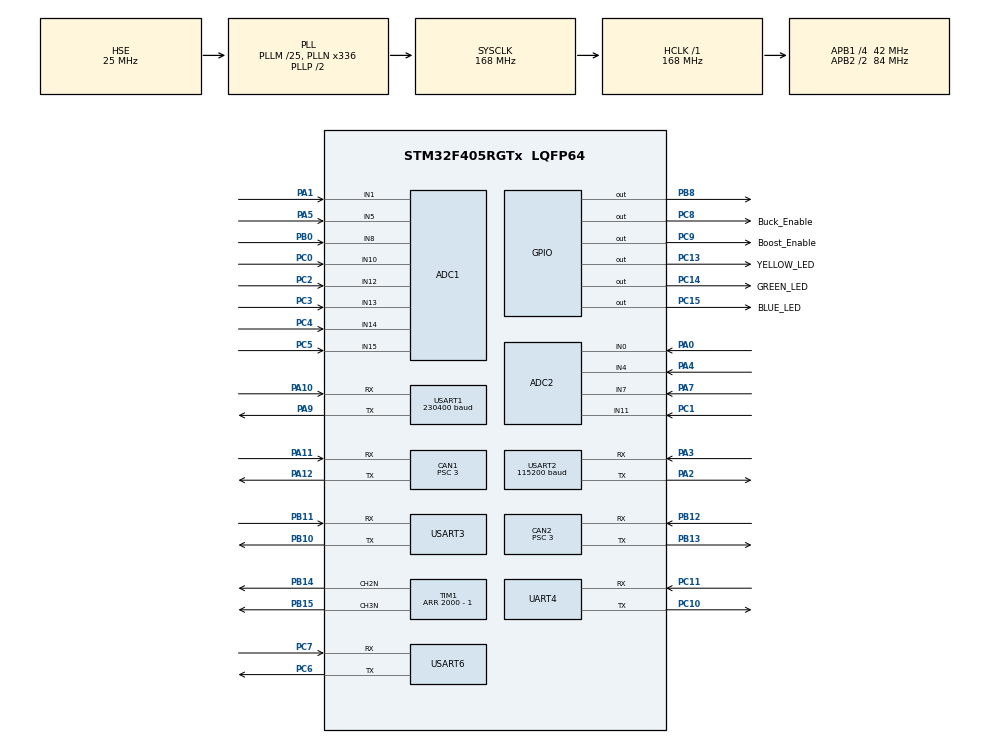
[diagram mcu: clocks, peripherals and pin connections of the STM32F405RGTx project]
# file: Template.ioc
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ADC1.Channel-0\#ChannelRegularConversion=ADC_CHANNEL_1
ADC1.Channel-1\#ChannelRegularConversion=ADC_CHANNEL_5
ADC1.Channel-2\#ChannelRegularConversion=ADC_CHANNEL_14
ADC1.Channel-3\#ChannelRegularConversion=ADC_CHANNEL_15
ADC1.Channel-4\#ChannelRegularConversion=ADC_CHANNEL_12
ADC1.Channel-5\#ChannelRegularConversion=ADC_CHANNEL_8
ADC1.Channel-6\#ChannelRegularConversion=ADC_CHANNEL_10
ADC1.Channel-7\#ChannelRegularConversion=ADC_CHANNEL_13
ADC1.ContinuousConvMode=ENABLE
ADC1.DMAContinuousRequests=ENABLE
ADC1.InjNumberOfConversion=0
ADC1.NbrOfConversion=8
ADC1.NbrOfConversionFlag=1
ADC1.Rank-0\#ChannelRegularConversion=1
ADC1.Rank-1\#ChannelRegularConversion=2
ADC1.Rank-2\#ChannelRegularConversion=3
ADC1.Rank-3\#ChannelRegularConversion=4
ADC1.Rank-4\#ChannelRegularConversion=5
ADC1.Rank-5\#ChannelRegularConversion=6
ADC1.Rank-6\#ChannelRegularConversion=7
ADC1.Rank-7\#ChannelRegularConversion=8
ADC1.SamplingTime-0\#ChannelRegularConversion=ADC_SAMPLETIME_56CYCLES
ADC1.SamplingTime-1\#ChannelRegularConversion=ADC_SAMPLETIME_56CYCLES
ADC1.SamplingTime-2\#ChannelRegularConversion=ADC_SAMPLETIME_56CYCLES
ADC1.SamplingTime-3\#ChannelRegularConversion=ADC_SAMPLETIME_56CYCLES
ADC1.SamplingTime-4\#ChannelRegularConversion=ADC_SAMPLETIME_56CYCLES
ADC1.SamplingTime-5\#ChannelRegularConversion=ADC_SAMPLETIME_56CYCLES
ADC1.SamplingTime-6\#ChannelRegularConversion=ADC_SAMPLETIME_56CYCLES
ADC1.SamplingTime-7\#ChannelRegularConversion=ADC_SAMPLETIME_56CYCLES
ADC1.ScanConvMode=ENABLE
ADC1.master=1
ADC2.Channel-0\#ChannelRegularConversion=ADC_CHANNEL_0
ADC2.Channel-2\#ChannelInjectedConversion=ADC_CHANNEL_0
ADC2.Channel-3\#ChannelInjectedConversion=ADC_CHANNEL_4
ADC2.Channel-4\#ChannelInjectedConversion=ADC_CHANNEL_11
ADC2.Channel-5\#ChannelInjectedConversion=ADC_CHANNEL_7
ADC2.ExternalTrigInjecConv=ADC_EXTERNALTRIGINJECCONV_T1_TRGO
ADC2.InjNumberOfConversion=4
ADC2.InjectedOffset-2\#ChannelInjectedConversion=0
ADC2.InjectedOffset-3\#ChannelInjectedConversion=0
ADC2.InjectedOffset-4\#ChannelInjectedConversion=0
ADC2.InjectedOffset-5\#ChannelInjectedConversion=0
ADC2.InjectedRank-2\#ChannelInjectedConversion=1
ADC2.InjectedRank-3\#ChannelInjectedConversion=2
ADC2.InjectedRank-4\#ChannelInjectedConversion=3
ADC2.InjectedRank-5\#ChannelInjectedConversion=4
ADC2.NbrOfConversion=1
ADC2.NbrOfConversionFlag=1
ADC2.Rank-0\#ChannelRegularConversion=1
ADC2.SamplingTime-0\#ChannelRegularConversion=ADC_SAMPLETIME_3CYCLES
ADC2.SamplingTime-2\#ChannelInjectedConversion=ADC_SAMPLETIME_56CYCLES
ADC2.SamplingTime-3\#ChannelInjectedConversion=ADC_SAMPLETIME_56CYCLES
ADC2.SamplingTime-4\#ChannelInjectedConversion=ADC_SAMPLETIME_56CYCLES
ADC2.SamplingTime-5\#ChannelInjectedConversion=ADC_SAMPLETIME_56CYCLES
CAN1.ABOM=ENABLE
CAN1.BS1=CAN_BS1_9TQ
CAN1.BS2=CAN_BS2_4TQ
CAN1.CalculateBaudRate=1000000
CAN1.CalculateTimeBit=1000
CAN1.CalculateTimeQuantum=71.42857142857143
CAN1.NART=ENABLE
CAN1.Prescaler=3
CAN2.ABOM=ENABLE
CAN2.BS1=CAN_BS1_9TQ
CAN2.BS2=CAN_BS2_4TQ
CAN2.CalculateBaudRate=1000000
CAN2.CalculateTimeBit=1000
CAN2.CalculateTimeQuantum=71.42857142857143
CAN2.NART=ENABLE
CAN2.Prescaler=3
Dma.ADC1.7.Direction=DMA_PERIPH_TO_MEMORY
Dma.ADC1.7.FIFOMode=DMA_FIFOMODE_DISABLE
Dma.ADC1.7.Instance=DMA2_Stream0
Dma.ADC1.7.MemDataAlignment=DMA_MDATAALIGN_WORD
Dma.ADC1.7.MemInc=DMA_MINC_ENABLE
Dma.ADC1.7.Mode=DMA_CIRCULAR
Dma.ADC1.7.PeriphDataAlignment=DMA_PDATAALIGN_WORD
Dma.ADC1.7.PeriphInc=DMA_PINC_DISABLE
Dma.ADC1.7.Priority=DMA_PRIORITY_LOW
Dma.Request0=USART1_RX
Dma.Request1=USART1_TX
Dma.Request10=UART4_TX
Dma.Request2=USART3_RX
Dma.Request3=USART3_TX
Dma.Request4=USART6_RX
Dma.Request5=USART6_TX
Dma.Request6=USART2_RX
Dma.Request7=ADC1
Dma.Request8=USART2_TX
Dma.Request9=UART4_RX
Dma.UART4_RX.9.Direction=DMA_PERIPH_TO_MEMORY
Dma.UART4_RX.9.FIFOMode=DMA_FIFOMODE_DISABLE
Dma.UART4_RX.9.Instance=DMA1_Stream2
Dma.UART4_RX.9.MemDataAlignment=DMA_MDATAALIGN_BYTE
Dma.UART4_RX.9.MemInc=DMA_MINC_ENABLE
Dma.UART4_RX.9.Mode=DMA_NORMAL
Dma.UART4_RX.9.PeriphDataAlignment=DMA_PDATAALIGN_BYTE
Dma.UART4_RX.9.PeriphInc=DMA_PINC_DISABLE
Dma.UART4_RX.9.Priority=DMA_PRIORITY_LOW
Dma.UART4_TX.10.Direction=DMA_MEMORY_TO_PERIPH
Dma.UART4_TX.10.FIFOMode=DMA_FIFOMODE_DISABLE
Dma.UART4_TX.10.Instance=DMA1_Stream4
Dma.UART4_TX.10.MemDataAlignment=DMA_MDATAALIGN_BYTE
Dma.UART4_TX.10.MemInc=DMA_MINC_ENABLE
Dma.UART4_TX.10.Mode=DMA_NORMAL
Dma.UART4_TX.10.PeriphDataAlignment=DMA_PDATAALIGN_BYTE
Dma.UART4_TX.10.PeriphInc=DMA_PINC_DISABLE
Dma.UART4_TX.10.Priority=DMA_PRIORITY_LOW
Dma.USART1_RX.0.Direction=DMA_PERIPH_TO_MEMORY
Dma.USART1_RX.0.FIFOMode=DMA_FIFOMODE_DISABLE
Dma.USART1_RX.0.Instance=DMA2_Stream2
Dma.USART1_RX.0.MemDataAlignment=DMA_MDATAALIGN_BYTE
Dma.USART1_RX.0.MemInc=DMA_MINC_ENABLE
Dma.USART1_RX.0.Mode=DMA_NORMAL
Dma.USART1_RX.0.PeriphDataAlignment=DMA_PDATAALIGN_BYTE
Dma.USART1_RX.0.PeriphInc=DMA_PINC_DISABLE
Dma.USART1_RX.0.Priority=DMA_PRIORITY_LOW
Dma.USART1_TX.1.Direction=DMA_MEMORY_TO_PERIPH
Dma.USART1_TX.1.FIFOMode=DMA_FIFOMODE_DISABLE
Dma.USART1_TX.1.Instance=DMA2_Stream7
Dma.USART1_TX.1.MemDataAlignment=DMA_MDATAALIGN_BYTE
Dma.USART1_TX.1.MemInc=DMA_MINC_ENABLE
Dma.USART1_TX.1.Mode=DMA_NORMAL
Dma.USART1_TX.1.PeriphDataAlignment=DMA_PDATAALIGN_BYTE
Dma.USART1_TX.1.PeriphInc=DMA_PINC_DISABLE
Dma.USART1_TX.1.Priority=DMA_PRIORITY_LOW
Dma.USART2_RX.6.Direction=DMA_PERIPH_TO_MEMORY
Dma.USART2_RX.6.FIFOMode=DMA_FIFOMODE_DISABLE
Dma.USART2_RX.6.Instance=DMA1_Stream5
Dma.USART2_RX.6.MemDataAlignment=DMA_MDATAALIGN_BYTE
Dma.USART2_RX.6.MemInc=DMA_MINC_ENABLE
Dma.USART2_RX.6.Mode=DMA_NORMAL
Dma.USART2_RX.6.PeriphDataAlignment=DMA_PDATAALIGN_BYTE
Dma.USART2_RX.6.PeriphInc=DMA_PINC_DISABLE
Dma.USART2_RX.6.Priority=DMA_PRIORITY_LOW
Dma.USART2_TX.8.Direction=DMA_MEMORY_TO_PERIPH
Dma.USART2_TX.8.FIFOMode=DMA_FIFOMODE_DISABLE
Dma.USART2_TX.8.Instance=DMA1_Stream6
Dma.USART2_TX.8.MemDataAlignment=DMA_MDATAALIGN_BYTE
Dma.USART2_TX.8.MemInc=DMA_MINC_ENABLE
Dma.USART2_TX.8.Mode=DMA_NORMAL
Dma.USART2_TX.8.PeriphDataAlignment=DMA_PDATAALIGN_BYTE
Dma.USART2_TX.8.PeriphInc=DMA_PINC_DISABLE
Dma.USART2_TX.8.Priority=DMA_PRIORITY_LOW
Dma.USART3_RX.2.Direction=DMA_PERIPH_TO_MEMORY
Dma.USART3_RX.2.FIFOMode=DMA_FIFOMODE_DISABLE
Dma.USART3_RX.2.Instance=DMA1_Stream1
Dma.USART3_RX.2.MemDataAlignment=DMA_MDATAALIGN_BYTE
Dma.USART3_RX.2.MemInc=DMA_MINC_ENABLE
Dma.USART3_RX.2.Mode=DMA_NORMAL
Dma.USART3_RX.2.PeriphDataAlignment=DMA_PDATAALIGN_BYTE
Dma.USART3_RX.2.PeriphInc=DMA_PINC_DISABLE
Dma.USART3_RX.2.Priority=DMA_PRIORITY_LOW
Dma.USART3_TX.3.Direction=DMA_MEMORY_TO_PERIPH
Dma.USART3_TX.3.FIFOMode=DMA_FIFOMODE_DISABLE
Dma.USART3_TX.3.Instance=DMA1_Stream3
Dma.USART3_TX.3.MemDataAlignment=DMA_MDATAALIGN_BYTE
Dma.USART3_TX.3.MemInc=DMA_MINC_ENABLE
Dma.USART3_TX.3.Mode=DMA_NORMAL
Dma.USART3_TX.3.PeriphDataAlignment=DMA_PDATAALIGN_BYTE
Dma.USART3_TX.3.PeriphInc=DMA_PINC_DISABLE
Dma.USART3_TX.3.Priority=DMA_PRIORITY_LOW
Dma.USART6_RX.4.Direction=DMA_PERIPH_TO_MEMORY
Dma.USART6_RX.4.FIFOMode=DMA_FIFOMODE_DISABLE
Dma.USART6_RX.4.Instance=DMA2_Stream1
Dma.USART6_RX.4.MemDataAlignment=DMA_MDATAALIGN_BYTE
Dma.USART6_RX.4.MemInc=DMA_MINC_ENABLE
Dma.USART6_RX.4.Mode=DMA_NORMAL
Dma.USART6_RX.4.PeriphDataAlignment=DMA_PDATAALIGN_BYTE
Dma.USART6_RX.4.PeriphInc=DMA_PINC_DISABLE
Dma.USART6_RX.4.Priority=DMA_PRIORITY_LOW
Dma.USART6_TX.5.Direction=DMA_MEMORY_TO_PERIPH
Dma.USART6_TX.5.FIFOMode=DMA_FIFOMODE_DISABLE
Dma.USART6_TX.5.Instance=DMA2_Stream6
Dma.USART6_TX.5.MemDataAlignment=DMA_MDATAALIGN_BYTE
Dma.USART6_TX.5.MemInc=DMA_MINC_ENABLE
Dma.USART6_TX.5.Mode=DMA_NORMAL
Dma.USART6_TX.5.PeriphDataAlignment=DMA_PDATAALIGN_BYTE
Dma.USART6_TX.5.PeriphInc=DMA_PINC_DISABLE
Dma.USART6_TX.5.Priority=DMA_PRIORITY_LOW
FREERTOS.INCLUDE_vTaskDelayUntil=1
FREERTOS.Tasks01=defaultTask,0,128,StartDefaultTask,Default,NULL
FREERTOS.configMAX_PRIORITIES=9
Mcu.Family=STM32F4
Mcu.Name=STM32F405RGTx
Mcu.Package=LQFP64
NVIC.ADC_IRQn=true\:0\:0\:true\:false\:true\:false\:true\:true\:true
NVIC.CAN1_RX0_IRQn=true\:5\:0\:false\:false\:true\:true\:true\:true\:true
NVIC.CAN1_RX1_IRQn=true\:5\:0\:false\:false\:true\:true\:true\:true\:true
NVIC.CAN2_RX0_IRQn=true\:5\:0\:false\:false\:true\:true\:true\:true\:true
NVIC.CAN2_RX1_IRQn=true\:5\:0\:false\:false\:true\:true\:true\:true\:true
NVIC.DMA1_Stream1_IRQn=true\:5\:0\:false\:false\:true\:true\:false\:true\:true
NVIC.DMA1_Stream2_IRQn=true\:5\:0\:false\:false\:true\:true\:true\:true\:true
NVIC.DMA1_Stream3_IRQn=true\:5\:0\:false\:false\:true\:true\:true\:true\:true
NVIC.DMA1_Stream4_IRQn=true\:5\:0\:false\:false\:true\:true\:true\:true\:true
NVIC.DMA1_Stream5_IRQn=true\:5\:0\:false\:false\:true\:true\:false\:true\:true
NVIC.DMA1_Stream6_IRQn=true\:5\:0\:false\:false\:true\:true\:true\:true\:true
NVIC.DMA2_Stream1_IRQn=true\:5\:0\:false\:false\:true\:true\:false\:true\:true
NVIC.DMA2_Stream2_IRQn=true\:5\:0\:false\:false\:true\:true\:false\:true\:true
NVIC.DMA2_Stream6_IRQn=true\:5\:0\:false\:false\:true\:true\:true\:true\:true
NVIC.DMA2_Stream7_IRQn=true\:5\:0\:false\:false\:true\:true\:true\:true\:true
NVIC.PriorityGroup=NVIC_PRIORITYGROUP_4
NVIC.TIM1_UP_TIM10_IRQn=true\:5\:0\:false\:false\:true\:true\:true\:true\:true
NVIC.TIM4_IRQn=true\:5\:0\:false\:false\:true\:true\:true\:true\:true
NVIC.TIM7_IRQn=true\:15\:0\:false\:false\:true\:false\:false\:true\:true
NVIC.TimeBase=TIM7_IRQn
NVIC.TimeBaseIP=TIM7
NVIC.UART4_IRQn=true\:5\:0\:false\:false\:true\:true\:true\:true\:true
NVIC.USART1_IRQn=true\:5\:0\:false\:false\:true\:true\:true\:true\:true
NVIC.USART2_IRQn=true\:5\:0\:false\:false\:true\:true\:true\:true\:true
NVIC.USART3_IRQn=true\:5\:0\:false\:false\:true\:true\:true\:true\:true
NVIC.USART6_IRQn=true\:5\:0\:false\:false\:true\:true\:true\:true\:true
PA0-WKUP.GPIO_Mode=GPIO_MODE_ANALOG
PA0-WKUP.GPIO_PuPd=GPIO_NOPULL
PA0-WKUP.Signal=ADCx_IN0
PA1.GPIO_Mode=GPIO_MODE_ANALOG
PA1.GPIO_PuPd=GPIO_NOPULL
PA1.Signal=ADCx_IN1
PA10.GPIO_PuPd=GPIO_PULLUP
PA10.Mode=Asynchronous
PA10.Signal=USART1_RX
PA11.GPIO_PuPd=GPIO_NOPULL
PA11.Mode=CAN_Activate
PA11.Signal=CAN1_RX
PA12.GPIO_PuPd=GPIO_NOPULL
PA12.Mode=CAN_Activate
PA12.Signal=CAN1_TX
PA13.Mode=Serial_Wire
PA13.Signal=SYS_JTMS-SWDIO
PA14.Mode=Serial_Wire
PA14.Signal=SYS_JTCK-SWCLK
PA2.GPIO_PuPd=GPIO_NOPULL
PA2.Mode=Asynchronous
PA2.Signal=USART2_TX
PA3.GPIO_PuPd=GPIO_PULLUP
PA3.Mode=Asynchronous
PA3.Signal=USART2_RX
PA4.GPIO_Mode=GPIO_MODE_ANALOG
PA4.GPIO_PuPd=GPIO_NOPULL
PA4.Signal=ADCx_IN4
PA5.GPIO_Mode=GPIO_MODE_ANALOG
PA5.GPIO_PuPd=GPIO_NOPULL
PA5.Signal=ADCx_IN5
PA7.Signal=ADCx_IN7
PA9.GPIO_PuPd=GPIO_NOPULL
PA9.Mode=Asynchronous
PA9.Signal=USART1_TX
PB0.GPIO_Mode=GPIO_MODE_ANALOG
PB0.GPIO_PuPd=GPIO_NOPULL
PB0.Signal=ADCx_IN8
PB10.GPIO_PuPd=GPIO_NOPULL
PB10.Mode=Asynchronous
PB10.Signal=USART3_TX
PB11.GPIO_PuPd=GPIO_PULLUP
PB11.Mode=Asynchronous
PB11.Signal=USART3_RX
PB12.GPIO_PuPd=GPIO_NOPULL
PB12.Mode=CAN_Activate
PB12.Signal=CAN2_RX
PB13.GPIO_PuPd=GPIO_NOPULL
PB13.Mode=CAN_Activate
PB13.Signal=CAN2_TX
PB14.GPIO_PuPd=GPIO_NOPULL
PB14.Mode=PWM Generation2 CH2N
PB14.Signal=TIM1_CH2N
PB15.GPIO_PuPd=GPIO_NOPULL
PB15.Mode=PWM Generation3 CH3N
PB15.Signal=TIM1_CH3N
PB8.Signal=GPIO_Output
PC0.GPIO_Mode=GPIO_MODE_ANALOG
PC0.GPIO_PuPd=GPIO_NOPULL
PC0.Signal=ADCx_IN10
PC1.GPIO_Mode=GPIO_MODE_ANALOG
PC1.GPIO_PuPd=GPIO_NOPULL
PC1.Signal=ADCx_IN11
PC10.GPIO_PuPd=GPIO_NOPULL
PC10.Mode=Asynchronous
PC10.Signal=UART4_TX
PC11.GPIO_PuPd=GPIO_PULLUP
PC11.Mode=Asynchronous
PC11.Signal=UART4_RX
PC13-ANTI_TAMP.GPIO_Label=YELLOW_LED
PC13-ANTI_TAMP.GPIO_PuPd=GPIO_NOPULL
PC13-ANTI_TAMP.PinState=GPIO_PIN_SET
PC13-ANTI_TAMP.Signal=GPIO_Output
PC14-OSC32_IN.GPIO_Label=GREEN_LED
PC14-OSC32_IN.GPIO_PuPd=GPIO_NOPULL
PC14-OSC32_IN.PinState=GPIO_PIN_SET
PC14-OSC32_IN.Signal=GPIO_Output
PC15-OSC32_OUT.GPIO_Label=BLUE_LED
PC15-OSC32_OUT.GPIO_PuPd=GPIO_NOPULL
PC15-OSC32_OUT.PinState=GPIO_PIN_SET
PC15-OSC32_OUT.Signal=GPIO_Output
PC2.GPIO_Mode=GPIO_MODE_ANALOG
PC2.GPIO_PuPd=GPIO_NOPULL
PC2.Signal=ADCx_IN12
PC3.GPIO_Mode=GPIO_MODE_ANALOG
PC3.GPIO_PuPd=GPIO_NOPULL
PC3.Signal=ADCx_IN13
PC4.GPIO_Mode=GPIO_MODE_ANALOG
PC4.GPIO_PuPd=GPIO_NOPULL
PC4.Signal=ADCx_IN14
PC5.GPIO_Mode=GPIO_MODE_ANALOG
PC5.GPIO_PuPd=GPIO_NOPULL
PC5.Signal=ADCx_IN15
PC6.GPIO_PuPd=GPIO_NOPULL
PC6.Mode=Asynchronous
PC6.Signal=USART6_TX
PC7.GPIO_PuPd=GPIO_PULLUP
PC7.Mode=Asynchronous
PC7.Signal=USART6_RX
PC8.GPIO_Label=Buck_Enable
PC8.GPIO_PuPd=GPIO_NOPULL
PC8.GPIO_Speed=GPIO_SPEED_FREQ_LOW
PC8.PinState=GPIO_PIN_RESET
PC8.Signal=GPIO_Output
PC9.GPIO_Label=Boost_Enable
PC9.GPIO_PuPd=GPIO_NOPULL
PC9.GPIO_Speed=GPIO_SPEED_FREQ_LOW
PC9.PinState=GPIO_PIN_RESET
PC9.Signal=GPIO_Output
PH0-OSC_IN.Mode=HSE-External-Oscillator
PH0-OSC_IN.Signal=RCC_OSC_IN
PH1-OSC_OUT.Mode=HSE-External-Oscillator
PH1-OSC_OUT.Signal=RCC_OSC_OUT
ProjectManager.HeapSize=0x200
ProjectManager.StackSize=0x400
ProjectManager.TargetToolchain=MDK-ARM V5.27
RCC.48MHZClocksFreq_Value=48000000
RCC.AHBFreq_Value=168000000
RCC.APB1CLKDivider=RCC_HCLK_DIV4
RCC.APB1Freq_Value=42000000
RCC.APB1TimFreq_Value=84000000
RCC.APB2CLKDivider=RCC_HCLK_DIV2
RCC.APB2Freq_Value=84000000
RCC.APB2TimFreq_Value=168000000
RCC.CortexFreq_Value=168000000
RCC.HCLKFreq_Value=168000000
RCC.HSE_VALUE=25000000
RCC.HSI_VALUE=16000000
RCC.LSE_VALUE=32768
RCC.PLLM=25
RCC.PLLN=336
RCC.PLLQ=7
RCC.PLLSourceVirtual=RCC_PLLSOURCE_HSE
RCC.SYSCLKFreq_VALUE=168000000
RCC.SYSCLKSource=RCC_SYSCLKSOURCE_PLLCLK
RCC.VCOOutputFreq_Value=336000000
SH.ADCx_IN0.0=ADC2_IN0,IN0
SH.ADCx_IN1.0=ADC1_IN1,IN1
SH.ADCx_IN10.0=ADC1_IN10,IN10
SH.ADCx_IN11.0=ADC2_IN11,IN11
SH.ADCx_IN12.0=ADC1_IN12,IN12
SH.ADCx_IN13.0=ADC1_IN13,IN13
SH.ADCx_IN14.0=ADC1_IN14,IN14
SH.ADCx_IN15.0=ADC1_IN15,IN15
SH.ADCx_IN4.0=ADC2_IN4,IN4
SH.ADCx_IN5.0=ADC1_IN5,IN5
SH.ADCx_IN7.0=ADC2_IN7,IN7
SH.ADCx_IN8.0=ADC1_IN8,IN8
TIM1.Channel-PWM\ Generation2\ CH2N=TIM_CHANNEL_2
TIM1.Channel-PWM\ Generation3\ CH3N=TIM_CHANNEL_3
TIM1.CounterMode=TIM_COUNTERMODE_CENTERALIGNED3
TIM1.OCFastMode_PWM-PWM\ Generation2\ CH2N=TIM_OCFAST_ENABLE
TIM1.OCFastMode_PWM-PWM\ Generation3\ CH3N=TIM_OCFAST_ENABLE
TIM1.Period=2000 - 1
TIM1.TIM_MasterOutputTrigger=TIM_TRGO_UPDATE
TIM4.Prescaler=83
UART4.VirtualMode=Asynchronous
USART1.BaudRate=230400
USART1.VirtualMode=VM_ASYNC
USART2.BaudRate=115200
USART2.Mode=MODE_TX_RX
USART2.Parity=PARITY_NONE
USART2.VirtualMode=VM_ASYNC
USART2.WordLength=WORDLENGTH_8B
USART3.VirtualMode=VM_ASYNC
USART6.VirtualMode=VM_ASYNC
VP_FREERTOS_VS_CMSIS_V1.Mode=CMSIS_V1
VP_SYS_VS_tim7.Mode=TIM7
VP_TIM4_VS_ClockSourceINT.Mode=Internal
board=custom

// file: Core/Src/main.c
/* USER CODE BEGIN Header */
/**
  ******************************************************************************
  * @file           : main.c
  * @brief          : Main program body
  ******************************************************************************
  * @attention
  *
  * <h2><center>&copy; Copyright (c) 2019 STMicroelectronics.
  * All rights reserved.</center></h2>
  *
  * This software component is licensed by ST under Ultimate Liberty license
  * SLA0044, the "License"; You may not use this file except in compliance with
  * the License. You may obtain a copy of the License at:
  *                             www.st.com/SLA0044
  *
  ******************************************************************************
  */
/* USER CODE END Header */
#include "main.h"
#include "cmsis_os.h"
#include "adc.h"
#include "can.h"
#include "dma.h"
#include "tim.h"
#include "usart.h"
#include "gpio.h"

/* USER CODE BEGIN Includes */
#include "SRML.h"
/* USER CODE END Includes */

void SystemClock_Config(void);
void MX_FREERTOS_Init(void);

int main(void)
{

  /* MCU Configuration--------------------------------------------------------*/

  /* Reset of all peripherals, Initializes the Flash interface and the Systick. */
  HAL_Init();

  /* Configure the system clock */
  SystemClock_Config();

  /* Initialize all configured peripherals */
  MX_GPIO_Init();
  MX_DMA_Init();
  MX_CAN1_Init();
  MX_CAN2_Init();
  MX_USART1_UART_Init();
  MX_USART2_UART_Init();
  MX_USART3_UART_Init();
  MX_USART6_UART_Init();
  MX_ADC1_Init();
  MX_TIM1_Init();
  MX_TIM4_Init();
  MX_UART4_Init();
  MX_ADC2_Init();
  /* USER CODE BEGIN 2 */
  System_Device_Init();
  /* USER CODE END 2 */

  /* Call init function for freertos objects (in freertos.c) */
  MX_FREERTOS_Init();

  /* Start scheduler */
  osKernelStart();

  /* We should never get here as control is now taken by the scheduler */
  /* Infinite loop */
  while (1)
  {

  }
}

void SystemClock_Config(void)
{
  RCC_OscInitTypeDef RCC_OscInitStruct = {0};
  RCC_ClkInitTypeDef RCC_ClkInitStruct = {0};

  /** Configure the main internal regulator output voltage
  */
  __HAL_RCC_PWR_CLK_ENABLE();
  __HAL_PWR_VOLTAGESCALING_CONFIG(PWR_REGULATOR_VOLTAGE_SCALE1);

  /** Initializes the RCC Oscillators according to the specified parameters
  * in the RCC_OscInitTypeDef structure.
  */
  RCC_OscInitStruct.OscillatorType = RCC_OSCILLATORTYPE_HSE;
  RCC_OscInitStruct.HSEState = RCC_HSE_ON;
  RCC_OscInitStruct.PLL.PLLState = RCC_PLL_ON;
  RCC_OscInitStruct.PLL.PLLSource = RCC_PLLSOURCE_HSE;
  RCC_OscInitStruct.PLL.PLLM = 25;
  RCC_OscInitStruct.PLL.PLLN = 336;
  RCC_OscInitStruct.PLL.PLLP = RCC_PLLP_DIV2;
  RCC_OscInitStruct.PLL.PLLQ = 7;
  if (HAL_RCC_OscConfig(&RCC_OscInitStruct) != HAL_OK)
  {
    Error_Handler();
  }

  /** Initializes the CPU, AHB and APB buses clocks
  */
  RCC_ClkInitStruct.ClockType = RCC_CLOCKTYPE_HCLK|RCC_CLOCKTYPE_SYSCLK
                              |RCC_CLOCKTYPE_PCLK1|RCC_CLOCKTYPE_PCLK2;
  RCC_ClkInitStruct.SYSCLKSource = RCC_SYSCLKSOURCE_PLLCLK;
  RCC_ClkInitStruct.AHBCLKDivider = RCC_SYSCLK_DIV1;
  RCC_ClkInitStruct.APB1CLKDivider = RCC_HCLK_DIV4;
  RCC_ClkInitStruct.APB2CLKDivider = RCC_HCLK_DIV2;

  if (HAL_RCC_ClockConfig(&RCC_ClkInitStruct, FLASH_LATENCY_5) != HAL_OK)
  {
    Error_Handler();
  }
}

void HAL_TIM_PeriodElapsedCallback(TIM_HandleTypeDef *htim)
{
  /* USER CODE BEGIN Callback 0 */
  if (htim->Instance == TIM4) {
    Update_SystemTick();
  }
  /* USER CODE END Callback 0 */
  if (htim->Instance == TIM7) {
    HAL_IncTick();
  }
}

void Error_Handler(void)
{
}

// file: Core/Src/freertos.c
/* USER CODE BEGIN Header */
/**
  ******************************************************************************
  * File Name          : freertos.c
  * Description        : Code for freertos applications
  ******************************************************************************
  * @attention
  *
  * <h2><center>&copy; Copyright (c) 2019 STMicroelectronics.
  * All rights reserved.</center></h2>
  *
  * This software component is licensed by ST under Ultimate Liberty license
  * SLA0044, the "License"; You may not use this file except in compliance with
  * the License. You may obtain a copy of the License at:
  *                             www.st.com/SLA0044
  *
  ******************************************************************************
  */
/* USER CODE END Header */

#include "FreeRTOS.h"
#include "task.h"
#include "main.h"
#include "cmsis_os.h"

osThreadId defaultTaskHandle;

void StartDefaultTask(void const * argument);

void MX_FREERTOS_Init(void); /* (MISRA C 2004 rule 8.1) */

/* GetIdleTaskMemory prototype (linked to static allocation support) */
void vApplicationGetIdleTaskMemory( StaticTask_t **ppxIdleTaskTCBBuffer, StackType_t **ppxIdleTaskStackBuffer, uint32_t *pulIdleTaskStackSize );

/* USER CODE BEGIN GET_IDLE_TASK_MEMORY */
static StaticTask_t xIdleTaskTCBBuffer;
static StackType_t xIdleStack[configMINIMAL_STACK_SIZE];

void vApplicationGetIdleTaskMemory( StaticTask_t **ppxIdleTaskTCBBuffer, StackType_t **ppxIdleTaskStackBuffer, uint32_t *pulIdleTaskStackSize )
{
  *ppxIdleTaskTCBBuffer = &xIdleTaskTCBBuffer;
  *ppxIdleTaskStackBuffer = &xIdleStack[0];
  *pulIdleTaskStackSize = configMINIMAL_STACK_SIZE;
  /* place for user code */
}
/* USER CODE END GET_IDLE_TASK_MEMORY */

void MX_FREERTOS_Init(void) {

  /* Create the thread(s) */
  /* definition and creation of defaultTask */
  osThreadDef(defaultTask, StartDefaultTask, osPriorityNormal, 0, 128);
  defaultTaskHandle = osThreadCreate(osThread(defaultTask), NULL);

}

void StartDefaultTask(void const * argument)
{
  /* USER CODE BEGIN StartDefaultTask */
	System_Task_Init();
  osThreadTerminate (defaultTaskHandle);

  /* Infinite loop */
  for(;;)
  {
    osDelay(1);
  }
  /* USER CODE END StartDefaultTask */
}
